# AT32F425 register map
Vendor: Keil; Series: AT32F425; File version: 1.0
CPU: CM4 r0p1, little endian, no MPU, FPU, 4 interrupt priority bits
Registers are 32-bit, read-write, reset 0x0 unless marked. A register's access mark holds for its fields unless they carry their own. Offsets are from the block's base; [hi:lo] are bit positions; {n}, {i} and the like mark numbered series; 'fields as' and 'values as' point back to an identical list.

## TMR1 — Advanced timer
Base 0x40012C00
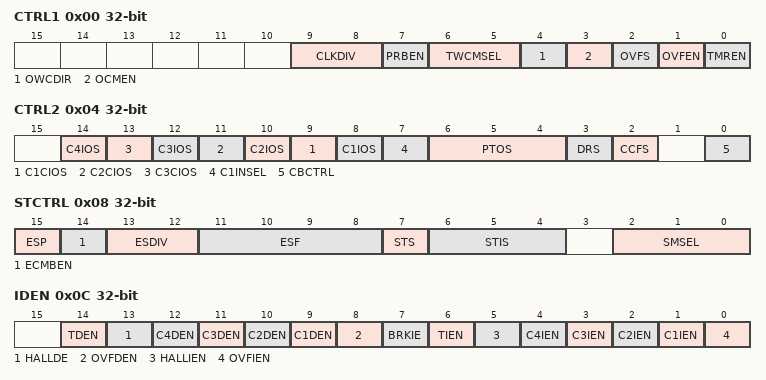
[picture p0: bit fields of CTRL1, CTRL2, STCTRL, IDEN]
0x00 CTRL1 — Control register 1
  [9:8] CLKDIV — Clock divider
    0=No division, fDTS=fCK_INT; 1=Div2 (Divided by 2, fDTS=fCK_INT/2); 2=Div4 (Divided by 4, fDTS=fCK_INT/4)
  [7] PRBEN — Period buffer enable
    on read: 0=Disabled (Period buffer is disabled); 1=Enabled (Period buffer is enabled) | on write: 0=Disable (Period buffer disable); 1=Enable (Period buffer enable)
  [6:5] TWCMSEL — Two-way count mode selection
    0=One-way counting mode, depending on the OWCDIR bit; 1=Mode1 (Two-way counting mode1, count up and down alternately, the CxIF bit is set only when the counter counts down); 2=Mode2 (Two-way counting mode2, count up and down alternately, the CxIF bit is set only when the counter counts up); 3=Mode3 (Two-way counting mode3, count up and down alternately, the CxIF bit is set when the counter counts up/down)
  [4] OWCDIR — One-way count direction
    0=Up; 1=Down
  [3] OCMEN — One cycle mode enable
    0=Continuous (The counter does not stop at an update event); 1=OneCycle (The counter stops at an update event)
  [2] OVFS — Overflow event source
    0=Any (Counter overflow, setting the OVFSWTR bit or overflow event generated by slave timer controller); 1=Counter (Only counter overflow generates an overflow event)
  [1] OVFEN — Overflow event enable
    on read: 0=Enabled (Overflow is enabled); 1=Disabled (Overflow is disabled) | on write: 0=Enable (Overflow enable); 1=Disable (Overflow disable)
  [0] TMREN — TMR enable
    on read: 0=Disabled (Timer is disabled); 1=Enabled (Timer is enabled) | on write: 0=Disable (Timer disable); 1=Enable (Timer enable)
0x04 CTRL2 — Control register 2
  [2n+7] C{n}CIOS (n=1..3) — Channel {n} complementary idle output state
    0=Low (After dead-time state is low); 1=High (After dead-time state is high)
  [2n+6] C{n}IOS (n=1..4) — Channel {n} idle output state
    values as C1CIOS
  [7] C1INSEL — C1IN selection
    0=CH1 (CH1 pin is connected to C1IRAW input); 1=XOR (The XOR result of CH1, CH2 and CH3 pins is connected to C1IRAW input)
  [6:4] PTOS — Primary TMR output selection
    0=Reset; 1=Enable; 2=Update; 3=ComparePulse; {v}=C{v-3}ORAW (C{v-3}ORAW signal) (v=4..7)
  [3] DRS — DMA request source
    0=Capture/compare event; 1=Overflow event
  [2] CCFS — Channel control bit refresh select
    0=Hall (Control bits are updated by setting the HALL bit); 1=TRGIN (Control bits are updated by setting the HALL bit or a rising edge on TRGIN)
  [0] CBCTRL — Channel buffer control
    on read: 0=Disabled (CxEN, CxCEN and CxOCTRL bits are not buffered); 1=Enabled (CxEN, CxCEN and CxOCTRL bits are buffered) | on write: 0=Disable (CxEN, CxCEN and CxOCTRL bits buffer disable); 1=Enable (CxEN, CxCEN and CxOCTRL bits buffer enable)
0x08 STCTRL — Subordinate TMR control register
  [15] ESP — External signal polarity
    0=High or rising edge; 1=Low (Low or falling edge)
  [14] ECMBEN — External clock mode B enable
    on read: 0=Disabled (External clock mode B is disabled); 1=Enabled (External clock mode B is enabled) | on write: 0=Disable (External clock mode B disable); 1=Enable (External clock mode B enable)
  [13:12] ESDIV — External signal divider
    0=Normal; 1=Div2 (Divided by 2); 2=Div4 (Divided by 4); 3=Div8 (Divided by 8)
  [11:8] ESF — External signal filter
    0=No filter, sampling is done at f_DTS; 1=N2 (f_sampling = f_DTS, N=2); 2=N4 (f_sampling = f_DTS, N=4); 3=N8 (f_sampling = f_DTS, N=8); 4=div2N6 (f_sampling = f_DTS/2, N=6); 5=div2N8 (f_sampling = f_DTS/2, N=8); 6=div4N6 (f_sampling = f_DTS/4, N=6); 7=div4N8 (f_sampling = f_DTS/4, N=8); 8=div8N6 (f_sampling = f_DTS/8, N=6); 9=div8N8 (f_sampling = f_DTS/8, N=8); 10=div16N5 (f_sampling = f_DTS/16, N=5); 11=div16N6 (f_sampling = f_DTS/16, N=6); 12=div16N8 (f_sampling = f_DTS/16, N=8); 13=div32N5 (f_sampling = f_DTS/32, N=5); 14=div32N6 (f_sampling = f_DTS/32, N=6); 15=div32N8 (f_sampling = f_DTS/32, N=8)
  [7] STS — Subordinate TMR synchronization
    on read: 0=Disabled (Subordinate TMR synchronization is disabled); 1=Enabled (Subordinate TMR synchronization is enabled) | on write: 0=Disable (Subordinate TMR synchronization disable); 1=Enable (Subordinate TMR synchronization enable)
  [6:4] STIS — Subordinate TMR input selection
    {v}=IS{v} (Internal selection {v}) (v=0..3); 4=C1INC (C1IRAW input detector); 5=C1IF1 (Filtered input 1); 6=C1IF2 (Filtered input 2); 7=EXT (External input)
  [2:0] SMSEL — Subordinate TMR mode selection
    0=Disabled (Slave mode is disabled); 1=EncoderA (Encoder mode A); 2=EncoderB (Encoder mode B); 3=EncoderC (Encoder mode C); 4=Reset mode - Rising edge of the TRGIN input reinitializes the counter; 5=Suspend mode - The counter starts counting when the TRGIN is high; 6=Trigger mode - A trigger event is generated at the rising edge of the TRGIN input; 7=External clock mode A - Rising edge of the TRGIN input clocks the counter
0x0C IDEN — Interrupt/DMA enable register
  [14] TDEN — Trigger DMA request enable
    on read: 0=Disabled (Trigger DMA request is disabled); 1=Enabled (Trigger DMA request is enabled) | on write: 0=Disable (Trigger DMA request disable); 1=Enable (Trigger DMA request enable)
  [13] HALLDE — HALL DMA request enable
    on read: 0=Disabled (HALL DMA request is disabled); 1=Enabled (HALL DMA request is enabled) | on write: 0=Disable (HALL DMA request disable); 1=Enable (HALL DMA request enable)
  [n+8] C{n}DEN (n=1..4) — Channel {n} DMA request enable
    on read: 0=Disabled (Channel DMA request is disabled); 1=Enabled (Channel DMA request is enabled) | on write: 0=Disable (Channel DMA request disable); 1=Enable (Channel DMA request enable)
  [8] OVFDEN — Overflow DMA request enable
    on read: 0=Disabled (Overflow event DMA request is disabled); 1=Enabled (Overflow event DMA request is enabled) | on write: 0=Disable (Overflow event DMA request disable); 1=Enable (Overflow event DMA request enable)
  [7] BRKIE — Brake interrupt enable
    on read: 0=Disabled (Break interrupt is disabled); 1=Enabled (Break interrupt is enabled) | on write: 0=Disable (Break interrupt disable); 1=Enable (Break interrupt enable)
  [6] TIEN — Trigger interrupt enable
    on read: 0=Disabled (Trigger interrupt is disabled); 1=Enabled (Trigger interrupt is enabled) | on write: 0=Disable (Trigger interrupt disable); 1=Enable (Trigger interrupt enable)
  [5] HALLIEN — HALL interrupt enable
    on read: 0=Disabled (HALL interrupt is disabled); 1=Enabled (HALL interrupt is enabled) | on write: 0=Disable (HALL interrupt disable); 1=Enable (HALL interrupt enable)
  [n] C{n}IEN (n=1..4) — Channel {n} interrupt enable
    on read: 0=Disabled (Channel interrupt is disabled); 1=Enabled (Channel interrupt is enabled) | on write: 0=Disable (Channel interrupt disable); 1=Enable (Channel interrupt enable)
  [0] OVFIEN — Overflow interrupt enable
    on read: 0=Disabled (Overflow interrupt is disabled); 1=Enabled (Overflow interrupt is enabled) | on write: 0=Disable (Overflow interrupt disable); 1=Enable (Overflow interrupt enable)
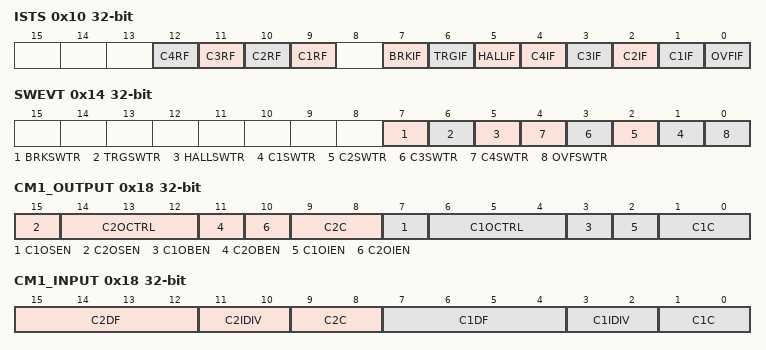
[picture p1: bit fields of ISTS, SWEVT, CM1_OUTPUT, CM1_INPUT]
0x10 ISTS — Interrupt status register
  [n+8] C{n}RF (n=1..4) write-0-clears — Channel {n} recapture flag
    on read: 0=NoEvent (No capture is detected); 1=Capture is detected | on write: 0=Clear (Recapture flag clear)
  [7] BRKIF write-0-clears — Brake interrupt flag
    on read: 0=Inactive level; 1=Active level | on write: 0=Clear (Break interrupt flag clear)
  [6] TRGIF write-0-clears — Trigger interrupt flag
    on read: 0=NoEvent (No trigger event occurs); 1=Trigger event is generated | on write: 0=Clear (Trigger interrupt flag clear)
  [5] HALLIF write-0-clears — HALL interrupt flag
    on read: 0=NoEvent (No hall event occurs); 1=Hall event is detected | on write: 0=Clear (Hall event flag clear)
  [n] C{n}IF (n=1..4) write-0-clears — Channel {n} interrupt flag
    on read: 0=NoEvent (No compare event occurs); 1=Capture/Compare event is generated | on write: 0=Clear (Interrupt flag clear)
  [0] OVFIF write-0-clears — Overflow interrupt flag
    on read: 0=No overflow event occurs; 1=Overflow (An overflow event is generated) | on write: 0=Clear (Overflow interrupt flag clear)
0x14 SWEVT wo — Software event register
  [7] BRKSWTR write-1-sets — Brake event triggered by software
    1=Event (Generate a break event)
  [6] TRGSWTR write-1-sets — Trigger event triggered by software
    on write: 1=TriggerEvent (Generate a trigger event)
  [5] HALLSWTR write-1-sets — HALL event triggered by software
    1=Event (Generate a HALL event)
  [n] C{n}SWTR (n=1..4) write-1-sets — Channel {n} event triggered by software
    on write: 1=ChannelEvent (Generate a channel event)
  [0] OVFSWTR write-1-sets — Overflow event triggered by software
    on write: 1=OverflowEvent (Generate an overflow event)
0x18 CM1_OUTPUT — Channel output mode register
  [9:8] C2C — Channel 2 configure
    0=Output (C2IN channel is configured as output); 1=C2IFP2 (Input, C2IN is mapped on C2IFP2); 2=C1IFP2 (Input, C2IN is mapped on C1IFP2); 3=STIS (Input, C2IN is mapped on STCI. This mode works only when the internal trigger input is selected by STIS.)
  [8n-1] C{n}OSEN (n=1..2) — Channel {n} output switch enable
    on read: 0=Disabled (CxORAW is not affected by EXT input); 1=Enabled (Once a high level is detect on EXT input, clear CxORAW) | on write: 0=Disable (CxORAW is not affected by EXT input); 1=Enable (Once a high level is detect on EXT input, clear CxORAW)
  [8n-2:8n-4] C{n}OCTRL (n=1..2) — Channel {n} output control
    0=Disconnected. CxORAW is disconnected from CxOUT; 1=High (CxORAW is high when TMRx_CVAL=TMRx_CxDT); 2=Low (CxORAW is low when TMRx_CVAL=TMRx_CxDT); 3=Toggle (Switch CxORAW level when TMRx_CVAL=TMRx_CxDT); 4=ForceLow (CxORAW is forced low); 5=ForceHigh (CxORAW is forced high); 6=PWM_A (PWM mode A); 7=PWM_B (PWM mode B)
  [8n-5] C{n}OBEN (n=1..2) — Channel {n} output buffer enable
    on read: 0=Disabled (Channel output buffer is disabled); 1=Enabled (Channel output buffer is enabled) | on write: 0=Disable (Channel output buffer disable); 1=Enable (Channel output buffer enable)
  [8n-6] C{n}OIEN (n=1..2) — Channel {n} output immediately enable
    0=Compare (Need to compare the CVAL with CxDT before generating an output); 1=Immediately (No need to compare the CVAL and CxDT. An output is generated immediately when a trigger event occurs.)
  [1:0] C1C — Channel 1 configure
    0=Output (C1IN channel is configured as output); 1=C1IFP1 (Input, C1IN is mapped on C1IFP1); 2=C2IFP1 (Input, C1IN is mapped on C2IFP1); 3=STIS (Input, C1IN is mapped on STCI. This mode works only when the internal trigger input is selected by STIS.)
0x18 CM1_INPUT (alternate view of CM1_OUTPUT) — Channel input mode register 1
  [9:8] C2C — Channel 2 configure
    values as CM1_OUTPUT.C2C
  [8n-1:8n-4] C{n}DF (n=1..2) — Channel {n} digital filter
    values as STCTRL.ESF
  [8n-5:8n-6] C{n}IDIV (n=1..2) — Channel {n} input divider
    0=Every (No divider. An input capture is generated at each active edge.); 1=Div2 (An input compare is generated every 2 active edges); 2=Div4 (An input compare is generated every 4 active edges); 3=Div8 (An input compare is generated every 8 active edges)
  [1:0] C1C — Channel 1 configure
    values as CM1_OUTPUT.C1C
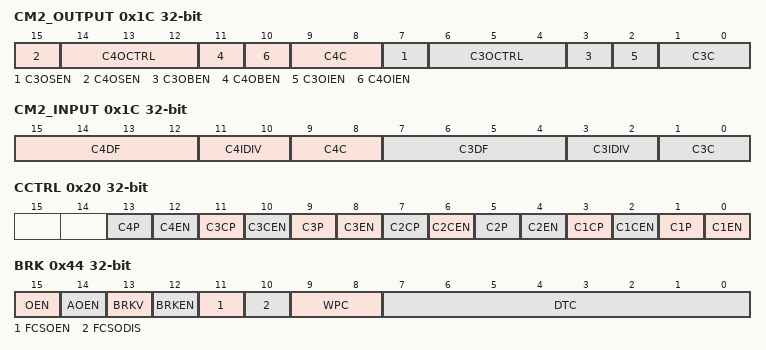
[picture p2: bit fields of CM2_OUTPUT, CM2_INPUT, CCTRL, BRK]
0x1C CM2_OUTPUT — Channel output mode register 2
  [9:8] C4C — Channel 4 configure
    0=Output (C4IN channel is configured as output); 1=C4IFP4 (Input, C4IN is mapped on C4IFP4); 2=C3IFP4 (Input, C4IN is mapped on C3IFP4); 3=STIS (Input, C4IN is mapped on STCI. This mode works only when the internal trigger input is selected by STIS.)
  [8n-17] C{n}OSEN (n=3..4) — Channel {n} output switch enable
    values as CM1_OUTPUT.C1OSEN
  [8n-18:8n-20] C{n}OCTRL (n=3..4) — Channel {n} output control
    values as CM1_OUTPUT.C1OCTRL
  [8n-21] C{n}OBEN (n=3..4) — Channel {n} output buffer enable
    values as CM1_OUTPUT.C1OBEN
  [8n-22] C{n}OIEN (n=3..4) — Channel {n} output immediately enable
    values as CM1_OUTPUT.C1OIEN
  [1:0] C3C — Channel 3 configure
    0=Output (C3IN channel is configured as output); 1=C3IFP3 (Input, C3IN is mapped on C3IFP3); 2=C4IFP3 (Input, C3IN is mapped on C4IFP3); 3=STIS (Input, C3IN is mapped on STCI. This mode works only when the internal trigger input is selected by STIS.)
0x1C CM2_INPUT (alternate view of CM2_OUTPUT) — Channel input mode register 2
  [9:8] C4C — Channel 4 configure
    values as CM2_OUTPUT.C4C
  [8n-17:8n-20] C{n}DF (n=3..4) — Channel {n} digital filter
    values as STCTRL.ESF
  [8n-21:8n-22] C{n}IDIV (n=3..4) — Channel {n} input divider
    values as CM1_INPUT.C1IDIV
  [1:0] C3C — Channel 3 configure
    values as CM2_OUTPUT.C3C
0x20 CCTRL — Channel control register
  [4n-1] C{n}CP (n=1..3) — Channel {n} complementary polarity
    0=High (Output active high or Input active rising edge); 1=Low (Output active low or Input active falling edge)
  [4n-2] C{n}CEN (n=1..3) — Channel {n} complementary enable
    on read: 0=Disabled (Channel is disabled); 1=Enabled (Channel is enabled) | on write: 0=Disable (Channel disable); 1=Enable (Channel enable)
  [4n-3] C{n}P (n=1..4) — Channel {n} polarity
    values as C1CP
  [4n-4] C{n}EN (n=1..4) — Channel {n} enable
    values as C1CEN
0x24 CVAL — Counter value
  [15:0] CVAL
0x28 DIV — Divider value
  [15:0] DIV — The counter clock frequency Fck_cnt = Ftmr_clk /({value}+1).
0x2C PR reset 0xFFFF — Period value
  [15:0] PR
0x30 RPR — Repetition of period value
  [7:0] RPR
{0x30+4i} C{i}DT (i=1..4) — Channel {i} data register
  [15:0] C1DT — Channel 1 data register
0x44 BRK — Brake register
  [15] OEN — Output enable
    on read: 0=Disabled (Output is disabled); 1=Enabled (Output is enabled) | on write: 0=Disable (Output disable); 1=Enable (Output enable)
  [14] AOEN — Automatic output enable
    on read: 0=Disabled (Automatic output is disabled); 1=Enabled (Automatic output is enabled) | on write: 0=Disable (Automatic output disable); 1=Enable (Automatic output enable)
  [13] BRKV — Brake input validity
    0=Low (Break input is active low); 1=High (Break input is active high)
  [12] BRKEN — Brake enable
    on read: 0=Disabled (Break input is disabled); 1=Enabled (Break input is enabled) | on write: 0=Disable (Break input disable); 1=Enable (Break input enable)
  [11] FCSOEN — Frozen channel status when holistic output enable
    on read: 0=Disabled (CxOUT/CxCOUT outputs are disabled); 1=Enabled (CxOUT/CxCOUT outputs are enabled) | on write: 0=Disable (CxOUT/CxCOUT outputs disable); 1=Enable (CxOUT/CxCOUT outputs enable)
  [10] FCSODIS — Frozen channel status when holistic output disable
    values as FCSOEN
  [9:8] WPC — Write protected configuration
    0=NoProtect (Write protection is OFF); 1=Level3 (Write protection level 3, and the following bits are write protected); 2=Level2 (Write protection level 2. The following bits and all bits in level 3 are write protected); 3=Level1 (Write protection level 1. The following bits and all bits in level 2 are write protected)
  [7:0] DTC — Dead-time configuration
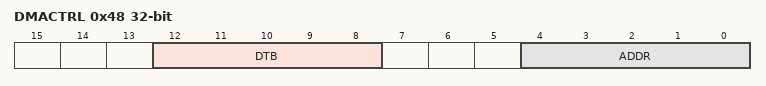
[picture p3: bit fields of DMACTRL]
0x48 DMACTRL — DMA control register
  [12:8] DTB range 0..17 — DMA transfer bytes
  [4:0] ADDR — DMA transfer address offset
0x4C DMADT — DMA data register
  [15:0] DMADT

## TMR2 — General purpose timer
Base 0x40000000
Registers as TMR1, without RPR, BRK; these are added or differ:
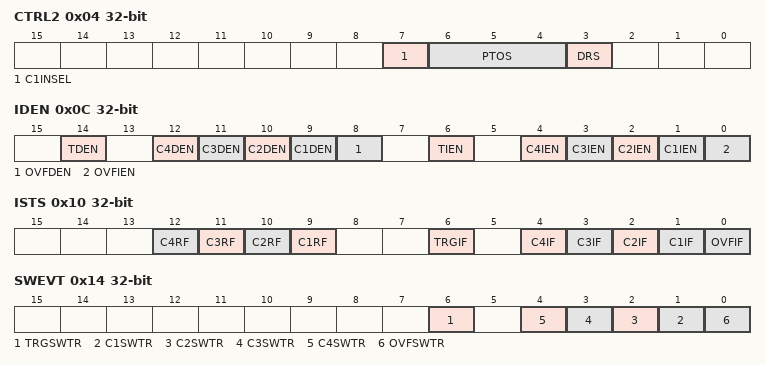
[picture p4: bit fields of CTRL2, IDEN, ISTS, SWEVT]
0x04 CTRL2 — Control register 2
  [7] C1INSEL — C1IN selection
    0=CH1 (CH1 pin is connected to C1IRAW input); 1=XOR (The XOR result of CH1, CH2 and CH3 pins is connected to C1IRAW input)
  [6:4] PTOS — Primary TMR output selection
    0=Reset; 1=Enable; 2=Update; 3=ComparePulse; {v}=C{v-3}ORAW (C{v-3}ORAW signal) (v=4..7)
  [3] DRS — DMA request source
    0=Capture/compare event; 1=Overflow event
0x0C IDEN — Interrupt/DMA enable register
  [14] TDEN — Trigger DMA request enable
    on read: 0=Disabled (Trigger DMA request is disabled); 1=Enabled (Trigger DMA request is enabled) | on write: 0=Disable (Trigger DMA request disable); 1=Enable (Trigger DMA request enable)
  [n+8] C{n}DEN (n=1..4) — Channel {n} DMA request enable
    on read: 0=Disabled (Channel DMA request is disabled); 1=Enabled (Channel DMA request is enabled) | on write: 0=Disable (Channel DMA request disable); 1=Enable (Channel DMA request enable)
  [8] OVFDEN — Overflow DMA request enable
    values as TMR1.IDEN.OVFDEN
  [6] TIEN — Trigger interrupt enable
    on read: 0=Disabled (Trigger interrupt is disabled); 1=Enabled (Trigger interrupt is enabled) | on write: 0=Disable (Trigger interrupt disable); 1=Enable (Trigger interrupt enable)
  [n] C{n}IEN (n=1..4) — Channel {n} interrupt enable
    on read: 0=Disabled (Channel interrupt is disabled); 1=Enabled (Channel interrupt is enabled) | on write: 0=Disable (Channel interrupt disable); 1=Enable (Channel interrupt enable)
  [0] OVFIEN — Overflow interrupt enable
    on read: 0=Disabled (Overflow interrupt is disabled); 1=Enabled (Overflow interrupt is enabled) | on write: 0=Disable (Overflow interrupt disable); 1=Enable (Overflow interrupt enable)
0x10 ISTS — Interrupt status register
  [n+8] C{n}RF (n=1..4) write-0-clears — Channel {n} recapture flag
    on read: 0=NoEvent (No capture is detected); 1=Capture is detected | on write: 0=Clear (Recapture flag clear)
  [6] TRGIF write-0-clears — Trigger interrupt flag
    on read: 0=NoEvent (No trigger event occurs); 1=Trigger event is generated | on write: 0=Clear (Trigger interrupt flag clear)
  [n] C{n}IF (n=1..4) write-0-clears — Channel {n} interrupt flag
    on read: 0=NoEvent (No compare event occurs); 1=Capture/Compare event is generated | on write: 0=Clear (Interrupt flag clear)
  [0] OVFIF write-0-clears — Overflow interrupt flag
    on read: 0=No overflow event occurs; 1=Overflow (An overflow event is generated) | on write: 0=Clear (Overflow interrupt flag clear)
0x14 SWEVT — Software event register
  [6] TRGSWTR write-1-sets — Trigger event triggered by software
    on write: 1=TriggerEvent (Generate a trigger event)
  [n] C{n}SWTR (n=1..4) write-1-sets — Channel {n} event triggered by software
    on write: 1=ChannelEvent (Generate a channel event)
  [0] OVFSWTR write-1-sets — Overflow event triggered by software
    on write: 1=OverflowEvent (Generate an overflow event)
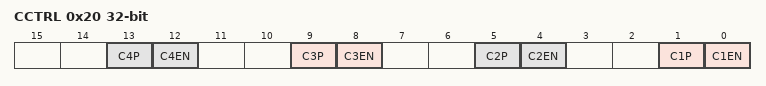
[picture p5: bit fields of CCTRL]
0x20 CCTRL — Channel control register
  [4n-3] C{n}P (n=1..4) — Channel {n} polarity
    0=High (Output active high or Input active rising edge); 1=Low (Output active low or Input active falling edge)
  [4n-4] C{n}EN (n=1..4) — Channel {n} enable
    on read: 0=Disabled (Channel is disabled); 1=Enabled (Channel is enabled) | on write: 0=Disable (Channel disable); 1=Enable (Channel enable)
0x2C PR — Period value
  [15:0] PR

## TMR3 — General purpose timer
Base 0x40000400
Registers as TMR2; these are added or differ:
0x2C PR reset 0xFFFF — Period value
  [15:0] PR
